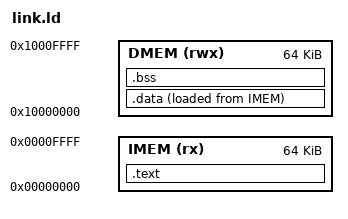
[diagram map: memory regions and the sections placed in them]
/* link.ld - memory layout for soc_top (see rtl/soc_top.v)
 *   IMEM 0x0000_0000 64 KiB : reset vector, code, read-only data, .data image
 *   DMEM 0x1000_0000 64 KiB : .data, .bss, stack (grows down from the top)
 */
OUTPUT_ARCH(riscv)
ENTRY(_start)

MEMORY
{
    IMEM (rx)  : ORIGIN = 0x00000000, LENGTH = 64K
    DMEM (rwx) : ORIGIN = 0x10000000, LENGTH = 64K
}

SECTIONS
{
    .text : {
        *(.text.init)
        *(.text*)
        *(.rodata*)
        *(.srodata*)
        . = ALIGN(4);
    } > IMEM

    .data : {
        _data_start = .;
        *(.data*)
        *(.sdata*)
        . = ALIGN(4);
        _data_end = .;
    } > DMEM AT > IMEM
    _data_lma = LOADADDR(.data);

    .bss (NOLOAD) : {
        _bss_start = .;
        *(.bss*)
        *(.sbss*)
        *(COMMON)
        . = ALIGN(4);
        _bss_end = .;
    } > DMEM

    _stack_top = ORIGIN(DMEM) + LENGTH(DMEM);
}
